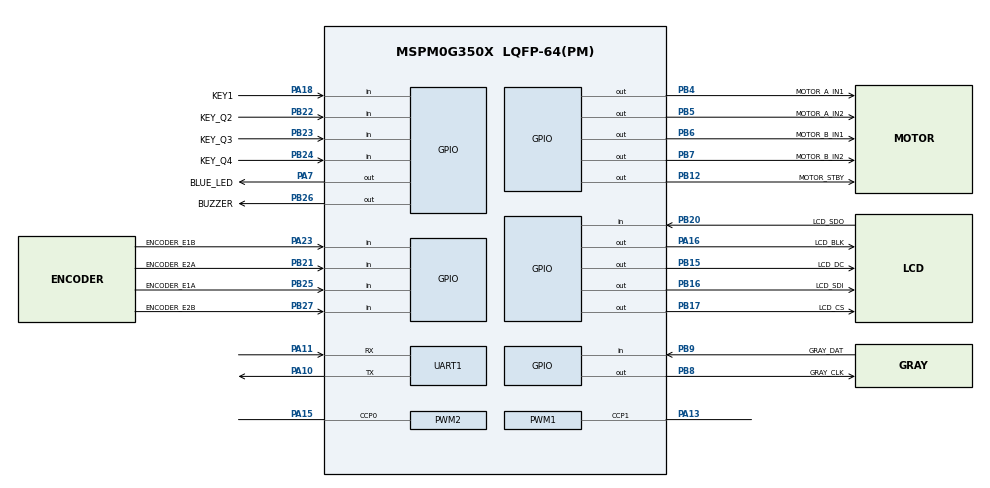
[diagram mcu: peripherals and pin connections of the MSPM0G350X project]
/**
 *
 * @cliArgs --device "MSPM0G350X" --part "Default" --package "LQFP-64(PM)" --product "mspm0_sdk@2.11.00.07"
 * @versions {"tool":"1.28.0+4696"}
 */

/**
 * Import the modules used in this configuration.
 */
const GPIO   = scripting.addModule("/ti/driverlib/GPIO", {}, false);
const GPIO1  = GPIO.addInstance();
const GPIO2  = GPIO.addInstance();
const GPIO3  = GPIO.addInstance();
const GPIO4  = GPIO.addInstance();
const GPIO5  = GPIO.addInstance();
const GPIO6  = GPIO.addInstance();
const GPIO7  = GPIO.addInstance();
const GPIO8  = GPIO.addInstance();
const GPIO9  = GPIO.addInstance();
const GPIO10 = GPIO.addInstance();
const GPIO11 = GPIO.addInstance();
const PWM    = scripting.addModule("/ti/driverlib/PWM", {}, false);
const PWM1   = PWM.addInstance();
const PWM2   = PWM.addInstance();
const SYSCTL = scripting.addModule("/ti/driverlib/SYSCTL");
const TIMER  = scripting.addModule("/ti/driverlib/TIMER", {}, false);
const TIMER1 = TIMER.addInstance();
const UART   = scripting.addModule("/ti/driverlib/UART", {}, false);
const UART1  = UART.addInstance();

/**
 * Write custom configuration values to the imported modules.
 */
GPIO1.$name                         = "MOTOR_CTRL";
GPIO1.port                          = "PORTB";
GPIO1.portSegment                   = "Lower";
GPIO1.associatedPins.create(5);
GPIO1.associatedPins[0].$name       = "MOTOR_A_IN1";
GPIO1.associatedPins[0].pin.$assign = "PB4";
GPIO1.associatedPins[1].$name       = "MOTOR_A_IN2";
GPIO1.associatedPins[1].pin.$assign = "PB5";
GPIO1.associatedPins[2].$name       = "MOTOR_B_IN1";
GPIO1.associatedPins[2].pin.$assign = "PB6";
GPIO1.associatedPins[3].$name       = "MOTOR_B_IN2";
GPIO1.associatedPins[3].pin.$assign = "PB7";
GPIO1.associatedPins[4].$name       = "MOTOR_STBY";
GPIO1.associatedPins[4].pin.$assign = "PB12";

const Board = scripting.addModule("/ti/driverlib/Board", {}, false);

GPIO2.$name                              = "GRAY_SERIAL";
GPIO2.port                               = "PORTB";
GPIO2.portSegment                        = "Lower";
GPIO2.associatedPins.create(2);
GPIO2.associatedPins[0].$name            = "GRAY_CLK";
GPIO2.associatedPins[0].pin.$assign      = "PB8";
GPIO2.associatedPins[1].$name            = "GRAY_DAT";
GPIO2.associatedPins[1].direction        = "INPUT";
GPIO2.associatedPins[1].internalResistor = "PULL_UP";
GPIO2.associatedPins[1].pin.$assign      = "PB9";

GPIO3.$name                         = "ENCODER_IO";
GPIO3.portSegment                   = "Upper";
GPIO3.port                          = "PORTB";
GPIO3.associatedPins.create(3);
GPIO3.associatedPins[0].$name       = "ENCODER_E1A";
GPIO3.associatedPins[0].direction   = "INPUT";
GPIO3.associatedPins[0].interruptEn = true;
GPIO3.associatedPins[0].polarity    = "RISE";
GPIO3.associatedPins[0].pin.$assign = "PB25";
GPIO3.associatedPins[1].$name       = "ENCODER_E2A";
GPIO3.associatedPins[1].direction   = "INPUT";
GPIO3.associatedPins[1].interruptEn = true;
GPIO3.associatedPins[1].polarity    = "RISE";
GPIO3.associatedPins[1].pin.$assign = "PB21";
GPIO3.associatedPins[2].$name       = "ENCODER_E2B";
GPIO3.associatedPins[2].direction   = "INPUT";
GPIO3.associatedPins[2].pin.$assign = "PB27";

GPIO4.$name                              = "START_KEY";
GPIO4.port                               = "PORTA";
GPIO4.portSegment                        = "Upper";
GPIO4.associatedPins[0].$name            = "KEY1";
GPIO4.associatedPins[0].direction        = "INPUT";
GPIO4.associatedPins[0].internalResistor = "PULL_UP";
GPIO4.associatedPins[0].pin.$assign      = "PA18";

GPIO5.$name                          = "BLUE_LED_PORT";
GPIO5.port                           = "PORTA";
GPIO5.portSegment                    = "Lower";
GPIO5.associatedPins[0].$name        = "BLUE_LED";
GPIO5.associatedPins[0].initialValue = "SET";
GPIO5.associatedPins[0].pin.$assign  = "PA7";

GPIO6.$name                         = "BUZZER_PORT";
GPIO6.port                          = "PORTB";
GPIO6.portSegment                   = "Upper";
GPIO6.associatedPins[0].$name       = "BUZZER";
GPIO6.associatedPins[0].pin.$assign = "PB26";

GPIO7.$name                         = "ENCODER_E1B_IO";
GPIO7.port                          = "PORTA";
GPIO7.portSegment                   = "Upper";
GPIO7.associatedPins[0].$name       = "ENCODER_E1B";
GPIO7.associatedPins[0].direction   = "INPUT";
GPIO7.associatedPins[0].pin.$assign = "PA23";

GPIO8.$name                          = "LCD_PORTA";
GPIO8.port                           = "PORTA";
GPIO8.portSegment                    = "Upper";
GPIO8.associatedPins.create(2);
GPIO8.associatedPins[0].$name        = "LCD_BLK";
GPIO8.associatedPins[0].initialValue = "SET";
GPIO8.associatedPins[0].pin.$assign  = "PA16";
GPIO8.associatedPins[1].$name        = "LCD_CLK";

GPIO9.$name                         = "LCD_CTRL";
GPIO9.port                          = "PORTB";
GPIO9.portSegment                   = "Lower";
GPIO9.associatedPins[0].$name       = "LCD_DC";
GPIO9.associatedPins[0].pin.$assign = "PB15";

GPIO10.$name                          = "LCD_SERIAL";
GPIO10.port                           = "PORTB";
GPIO10.portSegment                    = "Upper";
GPIO10.associatedPins.create(3);
GPIO10.associatedPins[0].$name        = "LCD_SDI";
GPIO10.associatedPins[0].pin.$assign  = "PB16";
GPIO10.associatedPins[1].$name        = "LCD_CS";
GPIO10.associatedPins[1].initialValue = "SET";
GPIO10.associatedPins[1].pin.$assign  = "PB17";
GPIO10.associatedPins[2].$name        = "LCD_SDO";
GPIO10.associatedPins[2].direction    = "INPUT";
GPIO10.associatedPins[2].pin.$assign  = "PB20";

GPIO11.$name                              = "MISSION_KEYS";
GPIO11.port                               = "PORTB";
GPIO11.portSegment                        = "Upper";
GPIO11.associatedPins.create(3);
GPIO11.associatedPins[0].$name            = "KEY_Q2";
GPIO11.associatedPins[0].direction        = "INPUT";
GPIO11.associatedPins[0].internalResistor = "PULL_DOWN";
GPIO11.associatedPins[0].pin.$assign      = "PB22";
GPIO11.associatedPins[1].$name            = "KEY_Q3";
GPIO11.associatedPins[1].direction        = "INPUT";
GPIO11.associatedPins[1].internalResistor = "PULL_DOWN";
GPIO11.associatedPins[1].pin.$assign      = "PB23";
GPIO11.associatedPins[2].$name            = "KEY_Q4";
GPIO11.associatedPins[2].direction        = "INPUT";
GPIO11.associatedPins[2].internalResistor = "PULL_DOWN";
GPIO11.associatedPins[2].pin.$assign      = "PB24";

PWM1.$name                              = "PWM_LEFT";
PWM1.dutyArgs                           = "[50,0,0,0]";
PWM1.pwmMode                            = "EDGE_ALIGN_UP";
PWM1.ccIndex                            = [1];
PWM1.timerCount                         = 1600;
PWM1.ccp1PinConfig.$name                = "ti_driverlib_gpio_GPIOPinGeneric1";
PWM1.ccp1PinConfig.direction            = scripting.forceWrite("OUTPUT");
PWM1.ccp1PinConfig.hideOutputInversion  = scripting.forceWrite(false);
PWM1.ccp1PinConfig.onlyInternalResistor = scripting.forceWrite(false);
PWM1.ccp1PinConfig.passedPeripheralType = scripting.forceWrite("Digital");
PWM1.peripheral.$assign                 = "TIMG0";
PWM1.peripheral.ccp1Pin.$assign         = "PA13";
PWM1.PWM_CHANNEL_1.$name                = "ti_driverlib_pwm_PWMTimerCC0";

PWM2.timerCount                         = 1600;
PWM2.$name                              = "PWM_RIGHT";
PWM2.pwmMode                            = "EDGE_ALIGN_UP";
PWM2.ccIndex                            = [0];
PWM2.PWM_CHANNEL_0.$name                = "ti_driverlib_pwm_PWMTimerCC1";
PWM2.ccp0PinConfig.direction            = scripting.forceWrite("OUTPUT");
PWM2.ccp0PinConfig.hideOutputInversion  = scripting.forceWrite(false);
PWM2.ccp0PinConfig.onlyInternalResistor = scripting.forceWrite(false);
PWM2.ccp0PinConfig.passedPeripheralType = scripting.forceWrite("Digital");
PWM2.ccp0PinConfig.$name                = "ti_driverlib_gpio_GPIOPinGeneric0";
PWM2.peripheral.$assign                 = "TIMA1";
PWM2.peripheral.ccp0Pin.$assign         = "PA15";

SYSCTL.forceDefaultClkConfig = true;

TIMER1.timerMode          = "PERIODIC";
TIMER1.timerPeriod        = "1ms";
TIMER1.timerStartTimer    = true;
TIMER1.$name              = "CONTROL_TIMER";
TIMER1.peripheral.$assign = "TIMG12";

UART1.$name                            = "GYRO_UART";
UART1.enabledInterrupts                = ["RX"];
UART1.peripheral.rxPin.$assign         = "PA11";
UART1.peripheral.txPin.$assign         = "PA10";
UART1.txPinConfig.$name                = "ti_driverlib_gpio_GPIOPinGeneric2";
UART1.txPinConfig.direction            = scripting.forceWrite("OUTPUT");
UART1.txPinConfig.hideOutputInversion  = scripting.forceWrite(false);
UART1.txPinConfig.onlyInternalResistor = scripting.forceWrite(false);
UART1.txPinConfig.passedPeripheralType = scripting.forceWrite("Digital");
UART1.rxPinConfig.$name                = "ti_driverlib_gpio_GPIOPinGeneric3";
UART1.rxPinConfig.hideOutputInversion  = scripting.forceWrite(false);
UART1.rxPinConfig.onlyInternalResistor = scripting.forceWrite(false);
UART1.rxPinConfig.passedPeripheralType = scripting.forceWrite("Digital");

/**
 * Pinmux solution for unlocked pins/peripherals. This ensures that minor changes to the automatic solver in a future
 * version of the tool will not impact the pinmux you originally saw.  These lines can be completely deleted in order to
 * re-solve from scratch.
 */
Board.peripheral.$suggestSolution            = "DEBUGSS";
Board.peripheral.swclkPin.$suggestSolution   = "PA20";
Board.peripheral.swdioPin.$suggestSolution   = "PA19";
GPIO8.associatedPins[1].pin.$suggestSolution = "PA17";
SYSCTL.peripheral.$suggestSolution           = "SYSCTL";
UART1.peripheral.$suggestSolution            = "UART0";
